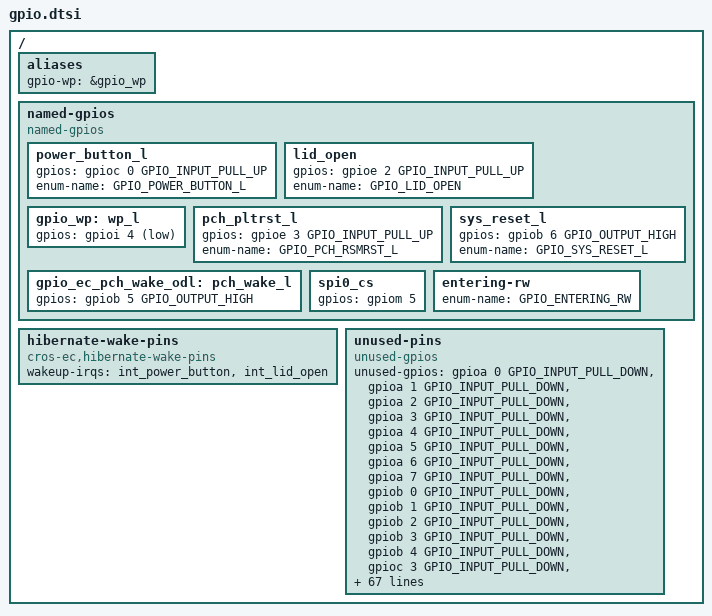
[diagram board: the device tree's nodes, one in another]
/* Copyright 2025 The ChromiumOS Authors
 * Use of this source code is governed by a BSD-style license that can be
 * found in the LICENSE file.
 */

#include <dt-bindings/gpio_defines.h>

/ {
	aliases {
		gpio-wp = &gpio_wp;
	};

	named-gpios {
		compatible = "named-gpios";

		power_button_l: power_button_l {
			gpios = <&gpioc 0 GPIO_INPUT_PULL_UP>;
			enum-name = "GPIO_POWER_BUTTON_L";
		};
		lid_open: lid_open {
			gpios = <&gpioe 2 GPIO_INPUT_PULL_UP>;
			enum-name = "GPIO_LID_OPEN";
		};
		gpio_wp: wp_l {
			gpios = <&gpioi 4 (GPIO_INPUT_PULL_UP |
					   GPIO_ACTIVE_LOW)>;
		};
		pch_pltrst_l {
			gpios = <&gpioe 3 GPIO_INPUT_PULL_UP>;
			enum-name = "GPIO_PCH_RSMRST_L";
		};
		sys_reset_l {
			gpios = <&gpiob 6 GPIO_OUTPUT_HIGH>;
			enum-name = "GPIO_SYS_RESET_L";
		};
		gpio_ec_pch_wake_odl: pch_wake_l {
			gpios = <&gpiob 5 GPIO_OUTPUT_HIGH>;
		};
		spi0_cs: spi0_cs {
			gpios = <&gpiom 5 (GPIO_INPUT | GPIO_VOLTAGE_1P8)>;
		};
		/* unimplemented GPIOs */
		entering-rw {
			enum-name = "GPIO_ENTERING_RW";
		};
	};

	hibernate-wake-pins {
		compatible = "cros-ec,hibernate-wake-pins";
		wakeup-irqs = <&int_power_button
			       &int_lid_open>;
	};

	unused-pins {
		compatible = "unused-gpios";

		unused-gpios =
			/* gpioa0 */
			<&gpioa 0 GPIO_INPUT_PULL_DOWN>,
			/* gpioa1 */
			<&gpioa 1 GPIO_INPUT_PULL_DOWN>,
			/* gpioa2 */
			<&gpioa 2 GPIO_INPUT_PULL_DOWN>,
			/* gpioa3 */
			<&gpioa 3 GPIO_INPUT_PULL_DOWN>,
			/* gpioa4 */
			<&gpioa 4 GPIO_INPUT_PULL_DOWN>,
			/* gpioa5 */
			<&gpioa 5 GPIO_INPUT_PULL_DOWN>,
			/* gpioa6 */
			<&gpioa 6 GPIO_INPUT_PULL_DOWN>,
			/* gpioa7 */
			<&gpioa 7 GPIO_INPUT_PULL_DOWN>,

			/* gpiob0 */
			<&gpiob 0 GPIO_INPUT_PULL_DOWN>,
			/* gpiob1 */
			<&gpiob 1 GPIO_INPUT_PULL_DOWN>,
			/* gpiob2 */
			<&gpiob 2 GPIO_INPUT_PULL_DOWN>,
			/* gpiob3 */
			<&gpiob 3 GPIO_INPUT_PULL_DOWN>,
			/* gpiob4 */
			<&gpiob 4 GPIO_INPUT_PULL_DOWN>,

			/* gpioc3 */
			<&gpioc 3 GPIO_INPUT_PULL_DOWN>,
			/* gpioc4 */
			<&gpioc 4 GPIO_INPUT_PULL_DOWN>,
			/* gpioc5 */
			<&gpioc 5 GPIO_INPUT_PULL_DOWN>,
			/* gpioc6 */
			<&gpioc 6 GPIO_INPUT_PULL_DOWN>,

			/* gpiod0 */
			<&gpiod 0 GPIO_INPUT_PULL_DOWN>,
			/* gpiod1 */
			<&gpiod 1 GPIO_INPUT_PULL_DOWN>,
			/* gpiod2 */
			<&gpiod 2 GPIO_OUTPUT_LOW>,
			/* gpiod3 */
			<&gpiod 3 GPIO_INPUT_PULL_DOWN>,
			/* gpiod4 */
			<&gpiod 4 GPIO_INPUT_PULL_DOWN>,
			/* gpiod5 */
			<&gpiod 5 GPIO_INPUT_PULL_DOWN>,
			/* gpiod6 */
			<&gpiod 6 GPIO_INPUT_PULL_DOWN>,
			/* gpiod7 */
			<&gpiod 7 GPIO_INPUT_PULL_DOWN>,

			/* gpioe1 */
			<&gpioe 1 GPIO_INPUT_PULL_DOWN>,
			/* gpioe4 */
			<&gpioe 4 GPIO_INPUT_PULL_DOWN>,
			/* gpioe5 */
			<&gpioe 5 GPIO_INPUT_PULL_DOWN>,

			/* gpiof0 */
			<&gpiof 0 GPIO_INPUT_PULL_DOWN>,
			/* gpiof1 */
			<&gpiof 1 GPIO_INPUT_PULL_DOWN>,
			/* gpiof4 */
			<&gpiof 4 GPIO_INPUT_PULL_DOWN>,
			/* gpiof5 */
			<&gpiof 5 GPIO_INPUT_PULL_DOWN>,

			/* gpiog0 */
			<&gpiog 0 GPIO_INPUT_PULL_DOWN>,
			/* gpiog1 */
			<&gpiog 1 GPIO_INPUT_PULL_DOWN>,
			/* gpiog2 */
			<&gpiog 2 GPIO_INPUT_PULL_DOWN>,
			/* gpiog6 */
			<&gpiog 6 GPIO_INPUT_PULL_DOWN>,

			/* gpioh0 */
			<&gpioh 0 GPIO_INPUT_PULL_DOWN>,

			/* gpioh3 */
			<&gpioh 3 GPIO_INPUT_PULL_DOWN>,
			/* gpioh4 */
			<&gpioh 4 GPIO_INPUT_PULL_DOWN>,
			/* gpioh5 */
			<&gpioh 5 GPIO_INPUT_PULL_DOWN>,
			/* gpioh6 */
			<&gpioh 6 GPIO_INPUT_PULL_DOWN>,
			/* gpioh7 */
			<&gpioh 7 GPIO_INPUT_PULL_DOWN>,


			/* gpioi6 */
			<&gpioi 6 GPIO_INPUT_PULL_DOWN>,
			/* gpioi7 */
			<&gpioi 7 GPIO_INPUT_PULL_DOWN>,

			/* gpioj0 */
			<&gpioj 0 GPIO_INPUT_PULL_DOWN>,
			/* gpioj1 */
			<&gpioj 1 GPIO_INPUT_PULL_DOWN>,
			/* gpioj3 */
			<&gpioj 3 GPIO_INPUT_PULL_DOWN>,
			/* gpioj4 */
			<&gpioj 4 GPIO_INPUT_PULL_DOWN>,
			/* gpioj5 */
			<&gpioj 5 GPIO_INPUT_PULL_DOWN>,
			/* gpioj6 */
			<&gpioj 6 GPIO_INPUT_PULL_DOWN>,
			/* gpioj7 */
			<&gpioj 7 GPIO_INPUT_PULL_DOWN>,

			/* gpiom0 */
			<&gpiom 0 GPIO_INPUT_PULL_DOWN>,
			/* gpiom1 */
			<&gpiom 1 GPIO_INPUT_PULL_DOWN>,
			/* gpiom2 */
			<&gpiom 2 GPIO_INPUT_PULL_DOWN>,
			/* gpiom3 */
			<&gpiom 3 GPIO_INPUT_PULL_DOWN>,
			/* gpiom4 */
			<&gpiom 4 GPIO_INPUT_PULL_DOWN>,
			/* gpiom6 */
			<&gpiom 6 GPIO_INPUT_PULL_DOWN>,

			/* gpiok0 */
			<&gpiok 0 GPIO_INPUT_PULL_DOWN>,
			/* gpiok1 */
			<&gpiok 1 GPIO_INPUT_PULL_DOWN>,
			/* gpiok2 */
			<&gpiok 2 GPIO_INPUT_PULL_DOWN>,
			/* gpiok3 */
			<&gpiok 3 GPIO_INPUT_PULL_DOWN>,
			/* gpiok4 */
			<&gpiok 4 GPIO_INPUT_PULL_DOWN>,
			/* gpiok5 */
			<&gpiok 5 GPIO_INPUT_PULL_DOWN>,
			/* gpiok6 */
			<&gpiok 6 GPIO_INPUT_PULL_DOWN>,
			/* gpiok7 */
			<&gpiok 7 GPIO_INPUT_PULL_DOWN>,

			/* gpiol0 */
			<&gpiol 0 GPIO_INPUT_PULL_DOWN>,
			/* gpiol1 */
			<&gpiol 1 GPIO_INPUT_PULL_DOWN>,
			/* gpiol2 */
			<&gpiol 2 GPIO_INPUT_PULL_DOWN>,
			/* gpiol3 */
			<&gpiol 3 GPIO_INPUT_PULL_DOWN>,
			/* gpiol4 */
			<&gpiol 4 GPIO_INPUT_PULL_DOWN>,
			/* gpiol5 */
			<&gpiol 5 GPIO_INPUT_PULL_DOWN>,
			/* gpiol6 */
			<&gpiol 6 GPIO_INPUT_PULL_DOWN>,
			/* gpiol7 */
			<&gpiol 7 GPIO_INPUT_PULL_DOWN>,

			/* gpion0 */
			<&gpion 0 GPIO_INPUT_PULL_DOWN>,
			/* gpion1 */
			<&gpion 1 GPIO_INPUT_PULL_DOWN>,
			/* gpion2 */
			<&gpion 2 GPIO_INPUT_PULL_DOWN>,
			/* gpion3 */
			<&gpion 3 GPIO_INPUT_PULL_DOWN>,
			/* gpion4 */
			<&gpion 4 GPIO_INPUT_PULL_DOWN>,
			/* gpion5 */
			<&gpion 5 GPIO_INPUT_PULL_DOWN>,
			/* gpion6 */
			<&gpion 6 GPIO_INPUT_PULL_DOWN>,
			/* gpion7 */
			<&gpion 7 GPIO_INPUT_PULL_DOWN>;
	};
};
